# MOTOR register map
Registers are 32-bit, access not given, no defined reset value unless marked. A register's access mark holds for its fields unless they carry their own. Addresses are absolute; registers are grouped by the start of their names; [hi:lo] are bit positions; {n}, {i} and the like mark numbered series; 'fields as' and 'values as' point back to an identical list.

## PWM
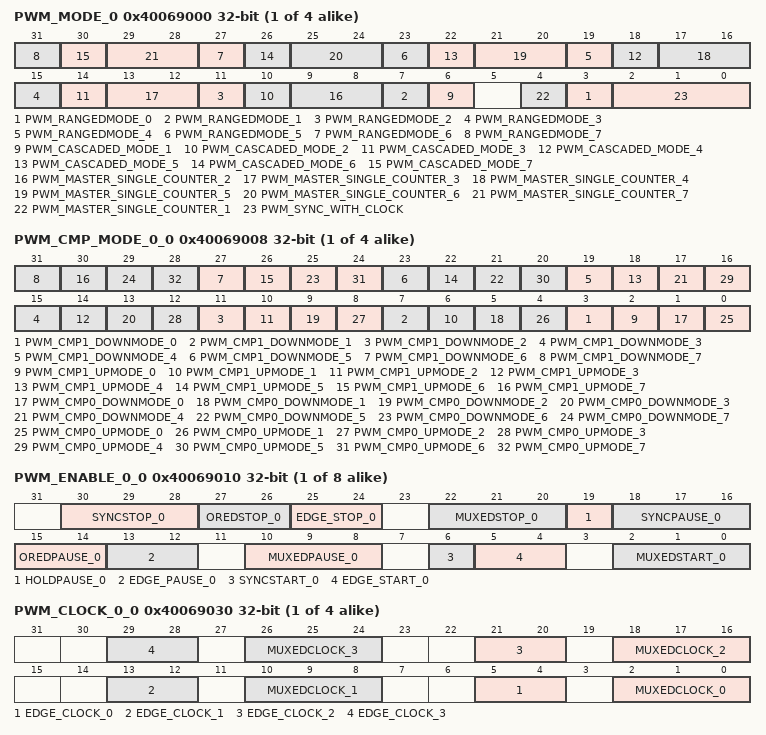
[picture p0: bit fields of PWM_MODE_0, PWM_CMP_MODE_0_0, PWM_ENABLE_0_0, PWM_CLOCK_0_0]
{0x40069000+0x400*i} PWM_MODE_{i} (i=0..3)
  [4n+3] PWM_RANGEDMODE_{n} (n=0..7), [4n+2] PWM_CASCADED_MODE_{n} (n=1..7), [4n+1:4n] PWM_MASTER_SINGLE_COUNTER_{n} (n=2..7), [4] PWM_MASTER_SINGLE_COUNTER_1, [2:0] PWM_SYNC_WITH_CLOCK
{0x40069008+0x400*i} PWM_CMP_MODE_0_{i} (i=0..3)
  [4n+3] PWM_CMP1_DOWNMODE_{n} (n=0..7), [4n+2] PWM_CMP1_UPMODE_{n} (n=0..7), [4n+1] PWM_CMP0_DOWNMODE_{n} (n=0..7), [4n] PWM_CMP0_UPMODE_{n} (n=0..7)
{0x40069010+4i} PWM_ENABLE_{i}_0 (i=0..7)
  [30:28] SYNCSTOP_{i}, [27:26] OREDSTOP_{i}, [25:24] EDGE_STOP_{i}, [22:20] MUXEDSTOP_{i}, [19] HOLDPAUSE_{i}, [18:16] SYNCPAUSE_{i}, [15:14] OREDPAUSE_{i}, [13:12] EDGE_PAUSE_{i}, [10:8] MUXEDPAUSE_{i}, [6] SYNCSTART_{i}, [5:4] EDGE_START_{i}, [2:0] MUXEDSTART_{i}
{0x40069030+0x400*i} PWM_CLOCK_0_{i} (i=0..3)
  [8n+5:8n+4] EDGE_CLOCK_{n} (n=0..3), [8n+2:8n] MUXEDCLOCK_{n} (n=0..3)
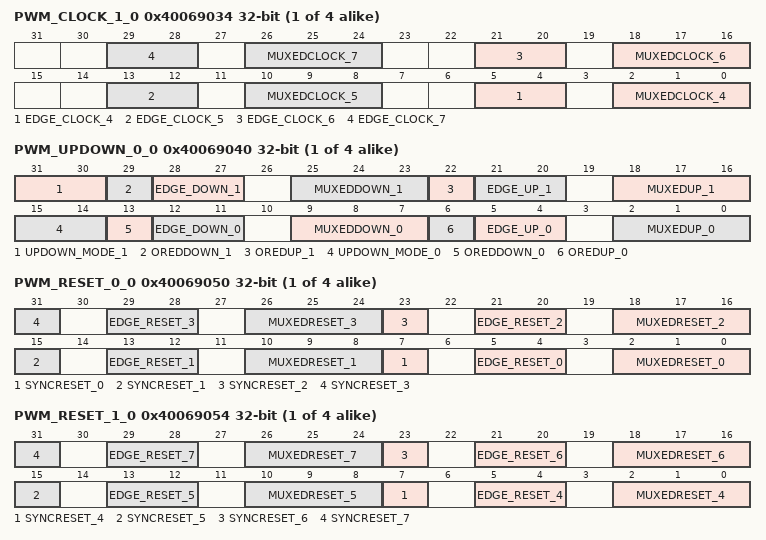
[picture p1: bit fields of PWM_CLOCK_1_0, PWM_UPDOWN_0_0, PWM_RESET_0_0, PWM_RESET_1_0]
{0x40069034+0x400*i} PWM_CLOCK_1_{i} (i=0..3)
  [8n-27:8n-28] EDGE_CLOCK_{n} (n=4..7), [8n-30:8n-32] MUXEDCLOCK_{n} (n=4..7)
{0x40069040+4i} PWM_UPDOWN_{i}_0 (i=0..3)
  [31:30] UPDOWN_MODE_{2i+1}, [29] OREDDOWN_{2i+1}, [28:27] EDGE_DOWN_{2i+1}, [25:23] MUXEDDOWN_{2i+1}, [22] OREDUP_{2i+1}, [21:20] EDGE_UP_{2i+1}, [18:16] MUXEDUP_{2i+1}, [15:14] UPDOWN_MODE_{2i}, [13] OREDDOWN_{2i}, [12:11] EDGE_DOWN_{2i}, [9:7] MUXEDDOWN_{2i}, [6] OREDUP_{2i}, [5:4] EDGE_UP_{2i}, [2:0] MUXEDUP_{2i}
{0x40069050+0x400*i} PWM_RESET_0_{i} (i=0..3)
  [8n+7] SYNCRESET_{n} (n=0..3), [8n+5:8n+4] EDGE_RESET_{n} (n=0..3), [8n+2:8n] MUXEDRESET_{n} (n=0..3)
{0x40069054+0x400*i} PWM_RESET_1_{i} (i=0..3)
  [8n-25] SYNCRESET_{n} (n=4..7), [8n-27:8n-28] EDGE_RESET_{n} (n=4..7), [8n-30:8n-32] MUXEDRESET_{n} (n=4..7)
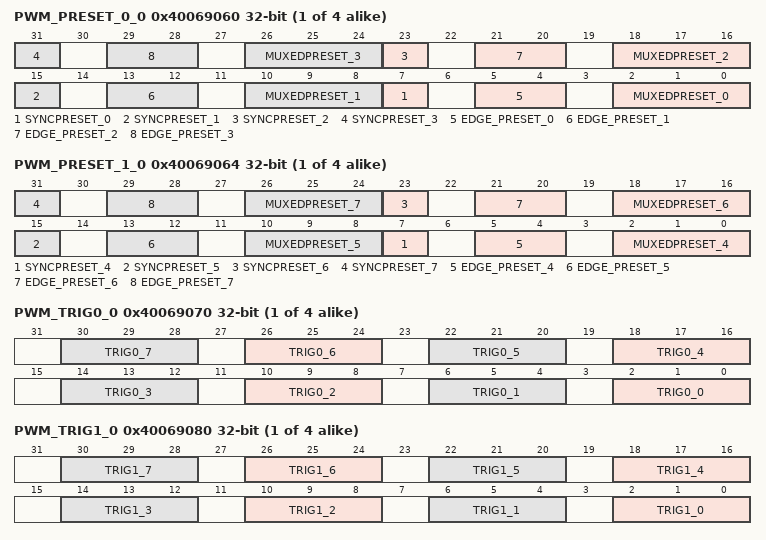
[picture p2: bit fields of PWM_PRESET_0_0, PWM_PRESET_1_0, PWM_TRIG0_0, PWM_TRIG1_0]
{0x40069060+0x400*i} PWM_PRESET_0_{i} (i=0..3)
  [8n+7] SYNCPRESET_{n} (n=0..3), [8n+5:8n+4] EDGE_PRESET_{n} (n=0..3), [8n+2:8n] MUXEDPRESET_{n} (n=0..3)
{0x40069064+0x400*i} PWM_PRESET_1_{i} (i=0..3)
  [8n-25] SYNCPRESET_{n} (n=4..7), [8n-27:8n-28] EDGE_PRESET_{n} (n=4..7), [8n-30:8n-32] MUXEDPRESET_{n} (n=4..7)
{0x40069070+0x400*i} PWM_TRIG0_{i} (i=0..3)
  [4n+2:4n] TRIG0_{n} (n=0..7)
{0x40069080+0x400*i} PWM_TRIG1_{i} (i=0..3)
  [4n+2:4n] TRIG1_{n} (n=0..7)
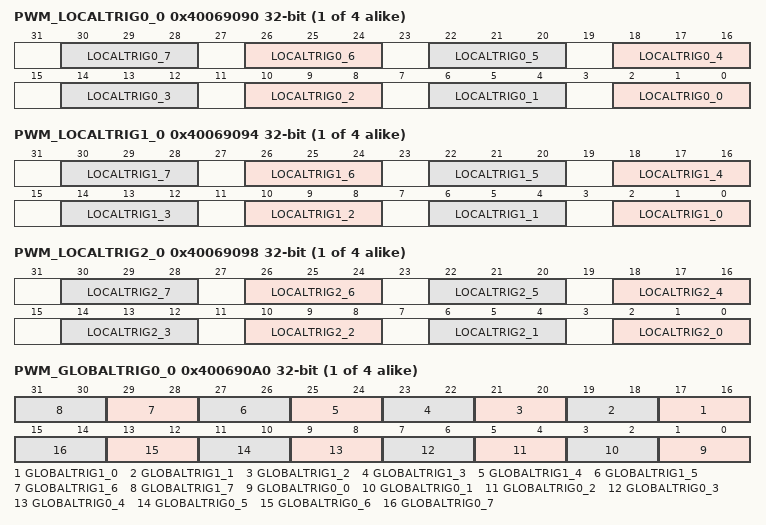
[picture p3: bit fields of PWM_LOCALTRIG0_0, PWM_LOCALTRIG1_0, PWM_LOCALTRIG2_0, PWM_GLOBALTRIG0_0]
{0x40069090+0x400*i} PWM_LOCALTRIG0_{i} (i=0..3)
  [4n+2:4n] LOCALTRIG0_{n} (n=0..7)
{0x40069094+0x400*i} PWM_LOCALTRIG1_{i} (i=0..3)
  [4n+2:4n] LOCALTRIG1_{n} (n=0..7)
{0x40069098+0x400*i} PWM_LOCALTRIG2_{i} (i=0..3)
  [4n+2:4n] LOCALTRIG2_{n} (n=0..7)
{0x400690A0+0x400*i} PWM_GLOBALTRIG0_{i} (i=0..3)
  [2n+17:2n+16] GLOBALTRIG1_{n} (n=0..7), [2n+1:2n] GLOBALTRIG0_{n} (n=0..7)
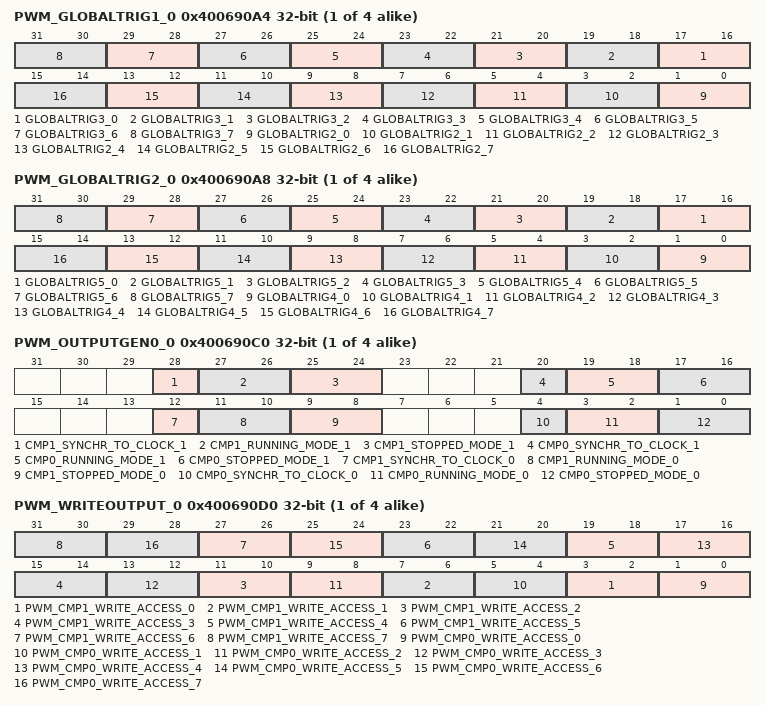
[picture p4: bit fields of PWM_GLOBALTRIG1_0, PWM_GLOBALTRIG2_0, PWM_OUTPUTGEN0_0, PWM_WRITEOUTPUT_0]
{0x400690A4+0x400*i} PWM_GLOBALTRIG1_{i} (i=0..3)
  [2n+17:2n+16] GLOBALTRIG3_{n} (n=0..7), [2n+1:2n] GLOBALTRIG2_{n} (n=0..7)
{0x400690A8+0x400*i} PWM_GLOBALTRIG2_{i} (i=0..3)
  [2n+17:2n+16] GLOBALTRIG5_{n} (n=0..7), [2n+1:2n] GLOBALTRIG4_{n} (n=0..7)
{0x400690C0+4i} PWM_OUTPUTGEN{i}_0 (i=0..3)
  [28] CMP1_SYNCHR_TO_CLOCK_{2i+1}, [27:26] CMP1_RUNNING_MODE_{2i+1}, [25:24] CMP1_STOPPED_MODE_{2i+1}, [20] CMP0_SYNCHR_TO_CLOCK_{2i+1}, [19:18] CMP0_RUNNING_MODE_{2i+1}, [17:16] CMP0_STOPPED_MODE_{2i+1}, [12] CMP1_SYNCHR_TO_CLOCK_{2i}, [11:10] CMP1_RUNNING_MODE_{2i}, [9:8] CMP1_STOPPED_MODE_{2i}, [4] CMP0_SYNCHR_TO_CLOCK_{2i}, [3:2] CMP0_RUNNING_MODE_{2i}, [1:0] CMP0_STOPPED_MODE_{2i}
{0x400690D0+0x400*i} PWM_WRITEOUTPUT_{i} wo (i=0..3)
  [4n+3:4n+2] PWM_CMP1_WRITE_ACCESS_{n} (n=0..7), [4n+1:4n] PWM_CMP0_WRITE_ACCESS_{n} (n=0..7)
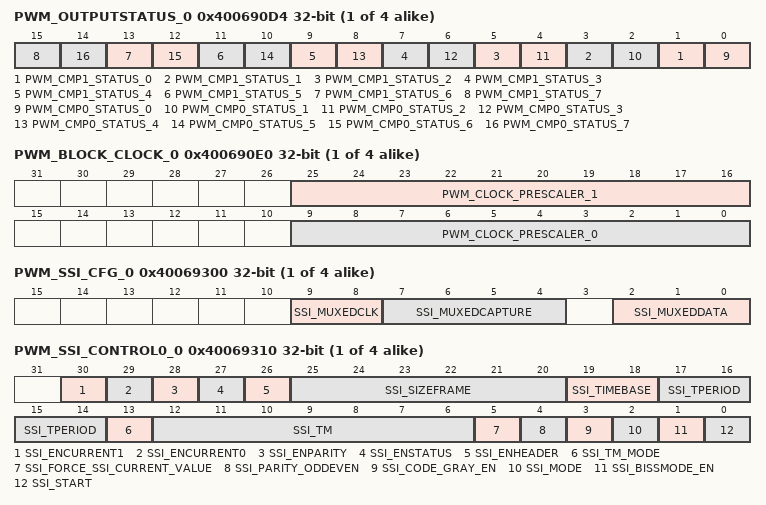
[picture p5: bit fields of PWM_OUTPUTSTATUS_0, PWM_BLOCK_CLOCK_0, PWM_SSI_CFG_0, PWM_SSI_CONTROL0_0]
{0x400690D4+0x400*i} PWM_OUTPUTSTATUS_{i} ro (i=0..3)
  [2n+1] PWM_CMP1_STATUS_{n} (n=0..7), [2n] PWM_CMP0_STATUS_{n} (n=0..7)
{0x400690E0+0x400*i} PWM_BLOCK_CLOCK_{i} (i=0..3)
  [25:16] PWM_CLOCK_PRESCALER_1, [9:0] PWM_CLOCK_PRESCALER_0
{0x40069300+0x400*i} PWM_SSI_CFG_{i} (i=0..3)
  [9:8] SSI_MUXEDCLK, [7:4] SSI_MUXEDCAPTURE, [2:0] SSI_MUXEDDATA
{0x40069310+0x400*i} PWM_SSI_CONTROL0_{i} (i=0..3)
  [30] SSI_ENCURRENT1, [29] SSI_ENCURRENT0, [28] SSI_ENPARITY, [27] SSI_ENSTATUS, [26] SSI_ENHEADER, [25:20] SSI_SIZEFRAME, [19:18] SSI_TIMEBASE, [17:14] SSI_TPERIOD, [13] SSI_TM_MODE, [12:6] SSI_TM, [5] SSI_FORCE_SSI_CURRENT_VALUE, [4] SSI_PARITY_ODDEVEN, [3] SSI_CODE_GRAY_EN, [2] SSI_MODE, [1] SSI_BISSMODE_EN, [0] SSI_START
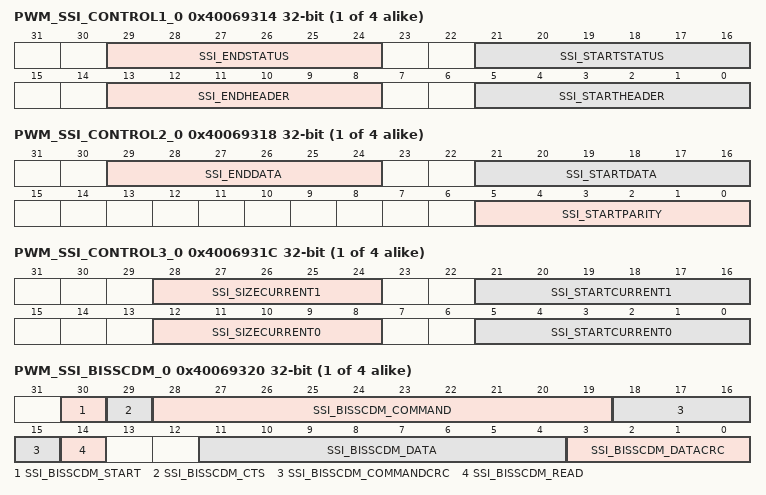
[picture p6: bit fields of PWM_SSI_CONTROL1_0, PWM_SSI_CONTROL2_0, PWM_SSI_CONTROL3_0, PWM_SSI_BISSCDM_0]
{0x40069314+0x400*i} PWM_SSI_CONTROL1_{i} (i=0..3)
  [29:24] SSI_ENDSTATUS, [21:16] SSI_STARTSTATUS, [13:8] SSI_ENDHEADER, [5:0] SSI_STARTHEADER
{0x40069318+0x400*i} PWM_SSI_CONTROL2_{i} (i=0..3)
  [29:24] SSI_ENDDATA, [21:16] SSI_STARTDATA, [5:0] SSI_STARTPARITY
{0x4006931C+0x400*i} PWM_SSI_CONTROL3_{i} (i=0..3)
  [28:24] SSI_SIZECURRENT1, [21:16] SSI_STARTCURRENT1, [12:8] SSI_SIZECURRENT0, [5:0] SSI_STARTCURRENT0
{0x40069320+0x400*i} PWM_SSI_BISSCDM_{i} (i=0..3)
  [30] SSI_BISSCDM_START, [29] SSI_BISSCDM_CTS, [28:19] SSI_BISSCDM_COMMAND, [18:15] SSI_BISSCDM_COMMANDCRC, [14] SSI_BISSCDM_READ, [11:4] SSI_BISSCDM_DATA, [3:0] SSI_BISSCDM_DATACRC
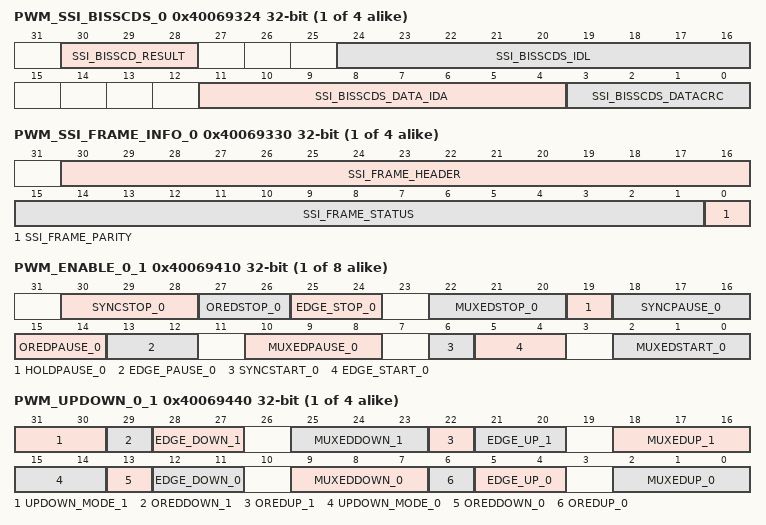
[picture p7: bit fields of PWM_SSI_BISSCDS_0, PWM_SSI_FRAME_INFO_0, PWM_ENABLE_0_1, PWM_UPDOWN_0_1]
{0x40069324+0x400*i} PWM_SSI_BISSCDS_{i} ro (i=0..3)
  [30:28] SSI_BISSCD_RESULT, [24:16] SSI_BISSCDS_IDL, [11:4] SSI_BISSCDS_DATA_IDA, [3:0] SSI_BISSCDS_DATACRC
{0x40069330+0x400*i} PWM_SSI_FRAME_INFO_{i} ro (i=0..3)
  [30:16] SSI_FRAME_HEADER, [15:1] SSI_FRAME_STATUS, [0] SSI_FRAME_PARITY
{0x40069340+0x400*i} PWM_SSI_FRAME_DATALOW_{i} ro (i=0..3)
  [31:0] SSI_FRAME_DATA_LOW
{0x40069344+0x400*i} PWM_SSI_FRAME_DATAHIGH_{i} ro (i=0..3)
  [31:0] SSI_FRAME_DATA_HIGH
{0x40069350+0x400*i} PWM_SSI_CURRENT0_{i} (i=0..3)
  [31:0] SSI_CURRENT0
{0x40069354+0x400*i} PWM_SSI_CURRENT1_{i} (i=0..3)
  [31:0] SSI_CURRENT1
{0x40069410+4i} PWM_ENABLE_{i}_1 (i=0..7)
  fields as PWM_ENABLE_0_0
{0x40069440+4i} PWM_UPDOWN_{i}_1 (i=0..3)
  fields as PWM_UPDOWN_0_0
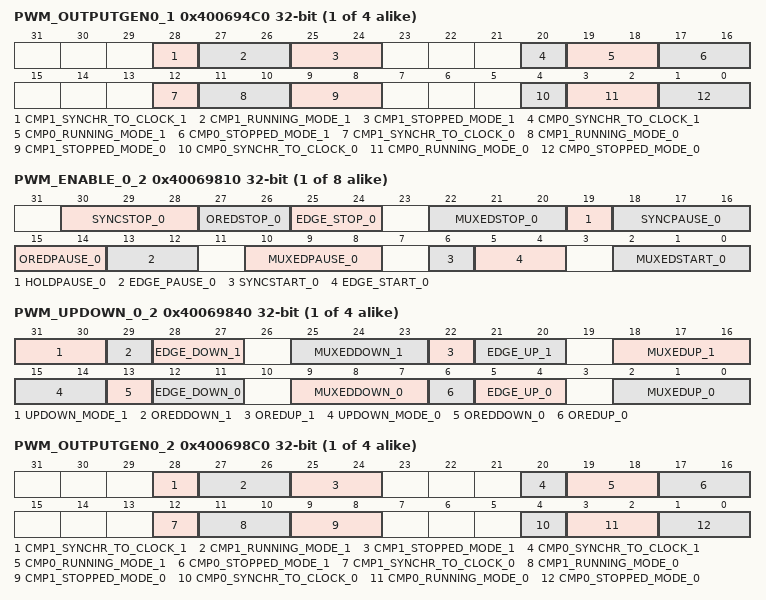
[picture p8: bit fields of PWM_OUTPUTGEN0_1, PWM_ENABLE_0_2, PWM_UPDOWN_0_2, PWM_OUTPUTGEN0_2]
{0x400694C0+4i} PWM_OUTPUTGEN{i}_1 (i=0..3)
  fields as PWM_OUTPUTGEN0_0
{0x40069810+4i} PWM_ENABLE_{i}_2 (i=0..7)
  fields as PWM_ENABLE_0_0
{0x40069840+4i} PWM_UPDOWN_{i}_2 (i=0..3)
  fields as PWM_UPDOWN_0_0
{0x400698C0+4i} PWM_OUTPUTGEN{i}_2 (i=0..3)
  fields as PWM_OUTPUTGEN0_0
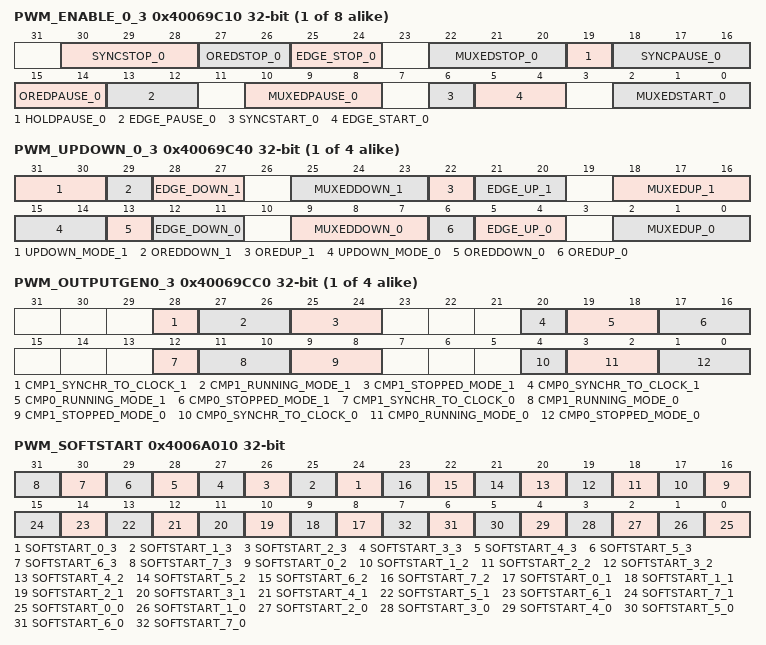
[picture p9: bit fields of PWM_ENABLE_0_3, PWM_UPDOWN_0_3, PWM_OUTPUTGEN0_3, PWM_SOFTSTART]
{0x40069C10+4i} PWM_ENABLE_{i}_3 (i=0..7)
  fields as PWM_ENABLE_0_0
{0x40069C40+4i} PWM_UPDOWN_{i}_3 (i=0..3)
  fields as PWM_UPDOWN_0_0
{0x40069CC0+4i} PWM_OUTPUTGEN{i}_3 (i=0..3)
  fields as PWM_OUTPUTGEN0_0
0x4006A010 PWM_SOFTSTART wo
  [n+24] SOFTSTART_{n}_3 (n=0..7), [n+16] SOFTSTART_{n}_2 (n=0..7), [n+8] SOFTSTART_{n}_1 (n=0..7), [n] SOFTSTART_{n}_0 (n=0..7)
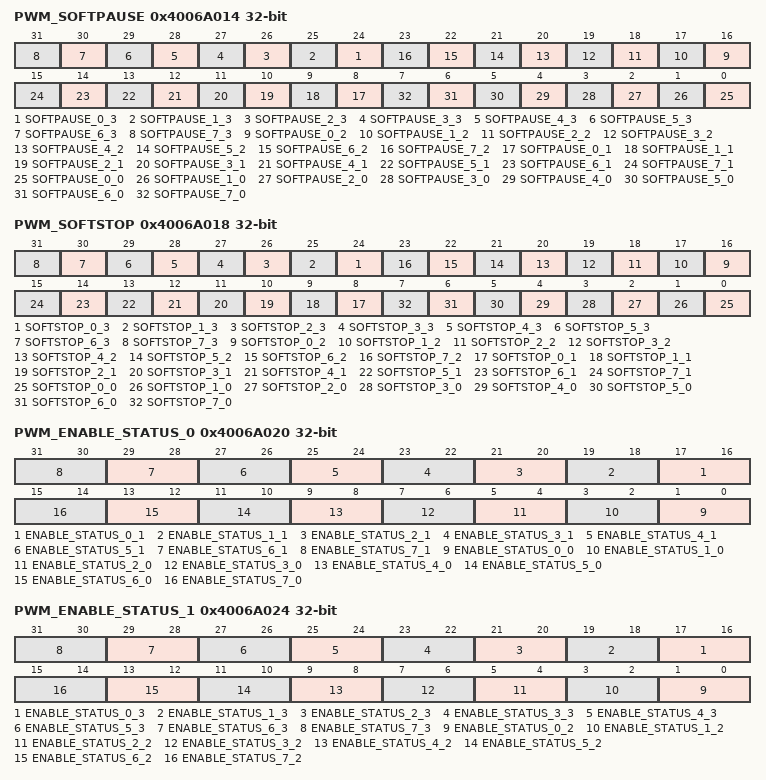
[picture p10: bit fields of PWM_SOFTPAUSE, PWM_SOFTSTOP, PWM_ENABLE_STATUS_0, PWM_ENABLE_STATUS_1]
0x4006A014 PWM_SOFTPAUSE wo
  [n+24] SOFTPAUSE_{n}_3 (n=0..7), [n+16] SOFTPAUSE_{n}_2 (n=0..7), [n+8] SOFTPAUSE_{n}_1 (n=0..7), [n] SOFTPAUSE_{n}_0 (n=0..7)
0x4006A018 PWM_SOFTSTOP wo
  [n+24] SOFTSTOP_{n}_3 (n=0..7), [n+16] SOFTSTOP_{n}_2 (n=0..7), [n+8] SOFTSTOP_{n}_1 (n=0..7), [n] SOFTSTOP_{n}_0 (n=0..7)
0x4006A020 PWM_ENABLE_STATUS_0 ro
  [2n+17:2n+16] ENABLE_STATUS_{n}_1 (n=0..7), [2n+1:2n] ENABLE_STATUS_{n}_0 (n=0..7)
0x4006A024 PWM_ENABLE_STATUS_1 ro
  [2n+17:2n+16] ENABLE_STATUS_{n}_3 (n=0..7), [2n+1:2n] ENABLE_STATUS_{n}_2 (n=0..7)
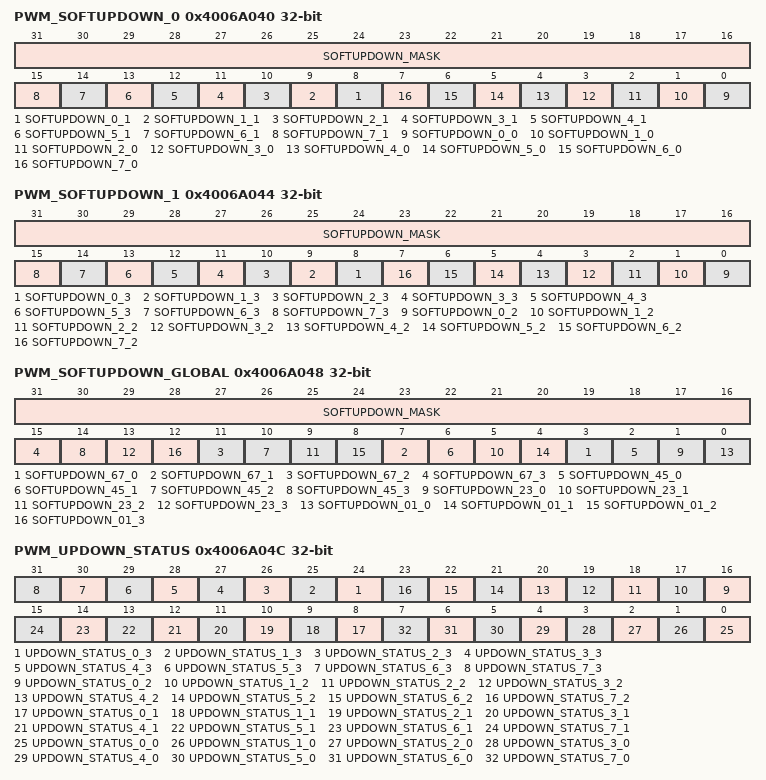
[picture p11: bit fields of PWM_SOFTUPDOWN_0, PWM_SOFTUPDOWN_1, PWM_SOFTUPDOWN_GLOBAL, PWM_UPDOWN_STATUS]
0x4006A040 PWM_SOFTUPDOWN_0 wo
  [31:16] SOFTUPDOWN_MASK, [n+8] SOFTUPDOWN_{n}_1 (n=0..7), [n] SOFTUPDOWN_{n}_0 (n=0..7)
0x4006A044 PWM_SOFTUPDOWN_1 wo
  [31:16] SOFTUPDOWN_MASK, [n+8] SOFTUPDOWN_{n}_3 (n=0..7), [n] SOFTUPDOWN_{n}_2 (n=0..7)
0x4006A048 PWM_SOFTUPDOWN_GLOBAL wo
  [31:16] SOFTUPDOWN_MASK, [4n+3] SOFTUPDOWN_67_{n} (n=0..3), [4n+2] SOFTUPDOWN_45_{n} (n=0..3), [4n+1] SOFTUPDOWN_23_{n} (n=0..3), [4n] SOFTUPDOWN_01_{n} (n=0..3)
0x4006A04C PWM_UPDOWN_STATUS ro
  [n+24] UPDOWN_STATUS_{n}_3 (n=0..7), [n+16] UPDOWN_STATUS_{n}_2 (n=0..7), [n+8] UPDOWN_STATUS_{n}_1 (n=0..7), [n] UPDOWN_STATUS_{n}_0 (n=0..7)
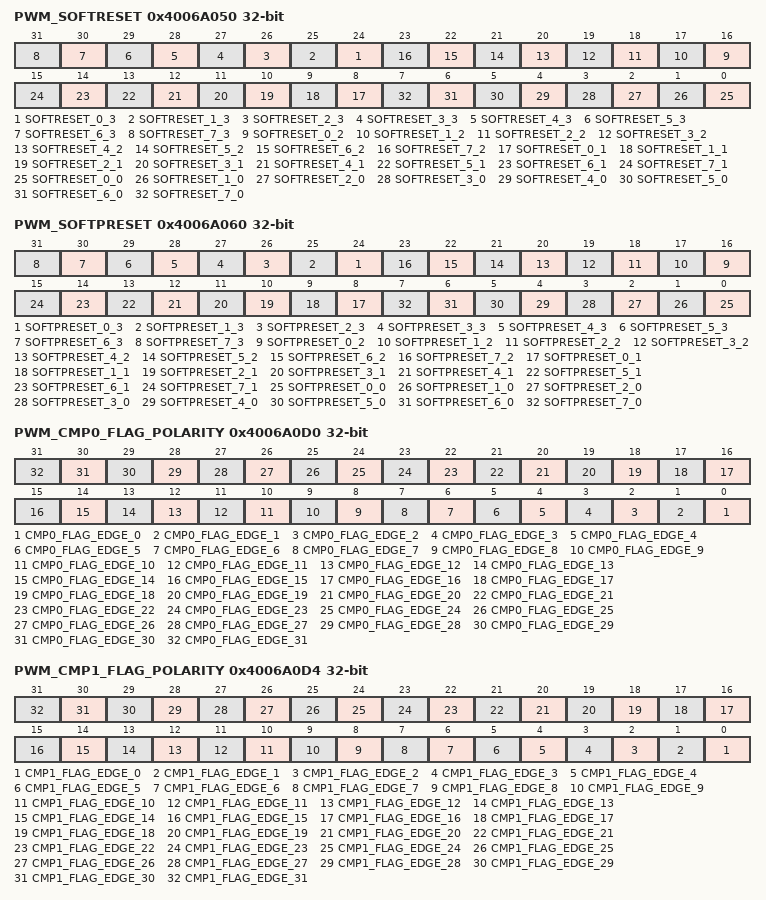
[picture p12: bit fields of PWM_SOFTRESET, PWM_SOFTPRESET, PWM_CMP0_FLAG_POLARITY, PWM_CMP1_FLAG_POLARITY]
0x4006A050 PWM_SOFTRESET wo
  [n+24] SOFTRESET_{n}_3 (n=0..7), [n+16] SOFTRESET_{n}_2 (n=0..7), [n+8] SOFTRESET_{n}_1 (n=0..7), [n] SOFTRESET_{n}_0 (n=0..7)
0x4006A060 PWM_SOFTPRESET wo
  [n+24] SOFTPRESET_{n}_3 (n=0..7), [n+16] SOFTPRESET_{n}_2 (n=0..7), [n+8] SOFTPRESET_{n}_1 (n=0..7), [n] SOFTPRESET_{n}_0 (n=0..7)
0x4006A0D0 PWM_CMP0_FLAG_POLARITY
  [n] CMP0_FLAG_EDGE_{n} (n=0..31)
0x4006A0D4 PWM_CMP1_FLAG_POLARITY
  [n] CMP1_FLAG_EDGE_{n} (n=0..31)
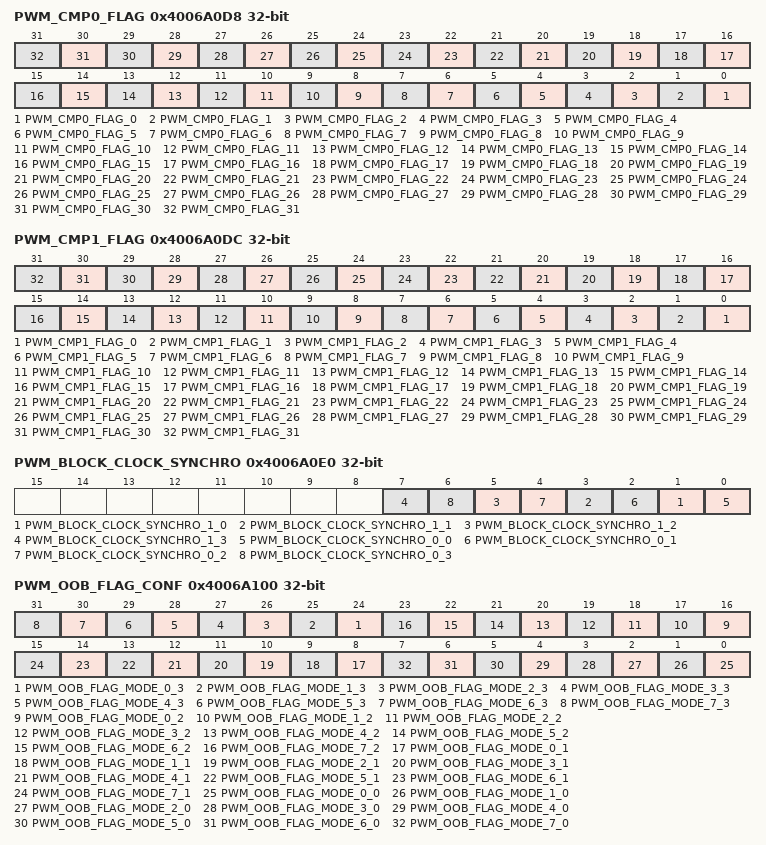
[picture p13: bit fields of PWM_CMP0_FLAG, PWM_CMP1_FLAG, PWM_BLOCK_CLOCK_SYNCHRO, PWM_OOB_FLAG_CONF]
0x4006A0D8 PWM_CMP0_FLAG
  [n] PWM_CMP0_FLAG_{n} (n=0..31)
0x4006A0DC PWM_CMP1_FLAG
  [n] PWM_CMP1_FLAG_{n} (n=0..31)
0x4006A0E0 PWM_BLOCK_CLOCK_SYNCHRO wo
  [2n+1] PWM_BLOCK_CLOCK_SYNCHRO_1_{n} (n=0..3), [2n] PWM_BLOCK_CLOCK_SYNCHRO_0_{n} (n=0..3)
0x4006A100 PWM_OOB_FLAG_CONF
  [n+24] PWM_OOB_FLAG_MODE_{n}_3 (n=0..7), [n+16] PWM_OOB_FLAG_MODE_{n}_2 (n=0..7), [n+8] PWM_OOB_FLAG_MODE_{n}_1 (n=0..7), [n] PWM_OOB_FLAG_MODE_{n}_0 (n=0..7)
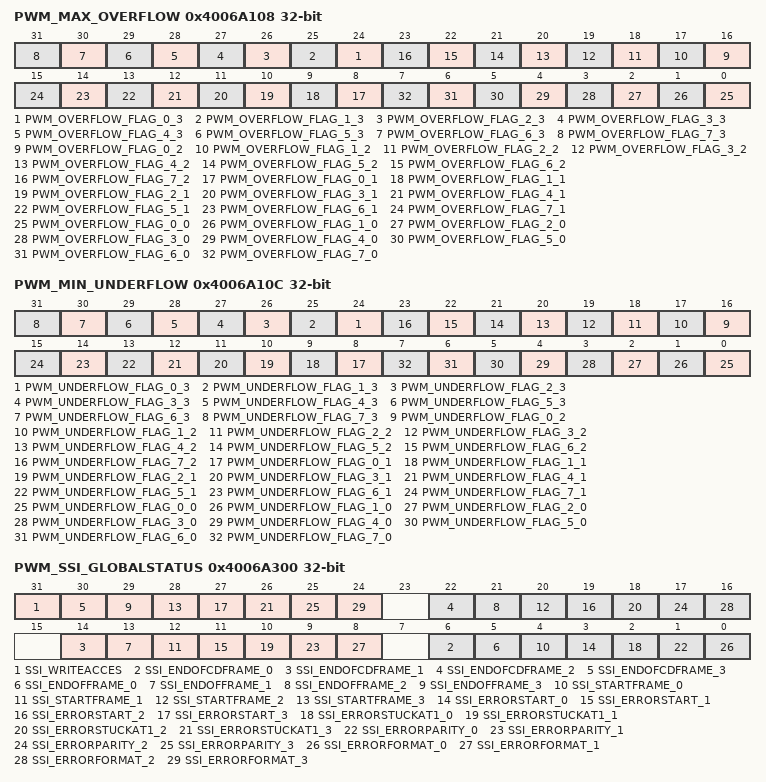
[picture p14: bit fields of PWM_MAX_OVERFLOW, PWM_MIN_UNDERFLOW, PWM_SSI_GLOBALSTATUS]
0x4006A108 PWM_MAX_OVERFLOW
  [n+24] PWM_OVERFLOW_FLAG_{n}_3 (n=0..7), [n+16] PWM_OVERFLOW_FLAG_{n}_2 (n=0..7), [n+8] PWM_OVERFLOW_FLAG_{n}_1 (n=0..7), [n] PWM_OVERFLOW_FLAG_{n}_0 (n=0..7)
0x4006A10C PWM_MIN_UNDERFLOW
  [n+24] PWM_UNDERFLOW_FLAG_{n}_3 (n=0..7), [n+16] PWM_UNDERFLOW_FLAG_{n}_2 (n=0..7), [n+8] PWM_UNDERFLOW_FLAG_{n}_1 (n=0..7), [n] PWM_UNDERFLOW_FLAG_{n}_0 (n=0..7)
0x4006A300 PWM_SSI_GLOBALSTATUS
  [31] SSI_WRITEACCES, [8n+6] SSI_ENDOFCDFRAME_{n} (n=0..3), [8n+5] SSI_ENDOFFRAME_{n} (n=0..3), [8n+4] SSI_STARTFRAME_{n} (n=0..3), [8n+3] SSI_ERRORSTART_{n} (n=0..3), [8n+2] SSI_ERRORSTUCKAT1_{n} (n=0..3), [8n+1] SSI_ERRORPARITY_{n} (n=0..3), [8n] SSI_ERRORFORMAT_{n} (n=0..3)
